# nrf5002 register map
Vendor: Nordic Semiconductor; Series: nRF50; File version: 1
CPU: CM0 r0p4, little endian, no MPU, no FPU, 2 interrupt priority bits, 32 interrupts
Registers are 32-bit, read-write, reset 0x0 unless marked. A register's access mark holds for its fields unless they carry their own. Offsets are from the block's base; [hi:lo] are bit positions; {n}, {i} and the like mark numbered series; 'fields as' and 'values as' point back to an identical list.

## RADIO (part 1 of 2) — 2.4 GHz radio
Base 0x40002000
0x00 TASKS_TXEN wo — Enable RADIO in TX mode
  [0] TASKS_TXEN
    1=Trigger task
0x04 TASKS_RXEN wo — Enable RADIO in RX mode
  [0] TASKS_RXEN
    1=Trigger task
0x08 TASKS_START wo — Start RADIO
  [0] TASKS_START
    1=Trigger task
0x0C TASKS_STOP wo — Stop RADIO
  [0] TASKS_STOP
    1=Trigger task
0x10 TASKS_DISABLE wo — Disable RADIO
  [0] TASKS_DISABLE
    1=Trigger task
0x14 TASKS_RSSISTART wo — Start the RSSI and take one single sample of the receive signal strength
  [0] TASKS_RSSISTART
    1=Trigger task
0x18 TASKS_RSSISTOP wo — Stop the RSSI measurement
  [0] TASKS_RSSISTOP
    1=Trigger task
0x1C TASKS_BCSTART wo — Start the bit counter
  [0] TASKS_BCSTART
    1=Trigger task
0x20 TASKS_BCSTOP wo — Stop the bit counter
  [0] TASKS_BCSTOP
    1=Trigger task
0x38 TASKS_CNTP_START wo — Start packet counter
  [0] TASKS_CNTP_START
    1=Trigger task
0x3C TASKS_CNTP_STOP wo — Stop packet counter
  [0] TASKS_CNTP_STOP
    1=Trigger task
0x40 TASKS_CNTP_CLEAR wo — Clear packet counter
  [0] TASKS_CNTP_CLEAR
    1=Trigger task
0x44 TASKS_DFESTART wo — Start an AoA/AoD procedure (antenna switching and baseband sampling)
  [0] TASKS_DFESTART
    1=Trigger task
0x48 TASKS_DFESTOP wo — Stop an AoA/AoD procedure
  [0] TASKS_DFESTOP
    1=Trigger task
0x50 TASKS_DMA_START wo — Start DMA transaction
  [0] TASKS_DMA_START
    1=Trigger task
0x54 TASKS_DMA_STOP wo — Stop ongoing DMA transaction
  [0] TASKS_DMA_STOP
    1=Trigger task
0x60 TASKS_ACQSTART wo — Start data acquisition
  [0] TASKS_ACQSTART
    1=Trigger task
0x64 TASKS_ACQSTOP wo — Stop data acquisition
  [0] TASKS_ACQSTOP
    1=Trigger task
0x68 TASKS_PCGC_PCP2_ZERO wo — Zero penalty
  [0] TASKS_PCGC_PCP2_ZERO
    1=Trigger task
0x6C TASKS_PCGC_PCP2_FULL wo — Full penalty
  [0] TASKS_PCGC_PCP2_FULL
    1=Trigger task
0x70 TASKS_PCGC_PCP1_ZERO wo — Zero penalty
  [0] TASKS_PCGC_PCP1_ZERO
    1=Trigger task
0x74 TASKS_PCGC_PCP1_FULL wo — Full penalty
  [0] TASKS_PCGC_PCP1_FULL
    1=Trigger task
0x78 TASKS_PCGC_PCP0_ZERO wo — Zero penalty
  [0] TASKS_PCGC_PCP0_ZERO
    1=Trigger task
0x7C TASKS_PCGC_PCP0_FULL wo — Full penalty
  [0] TASKS_PCGC_PCP0_FULL
    1=Trigger task
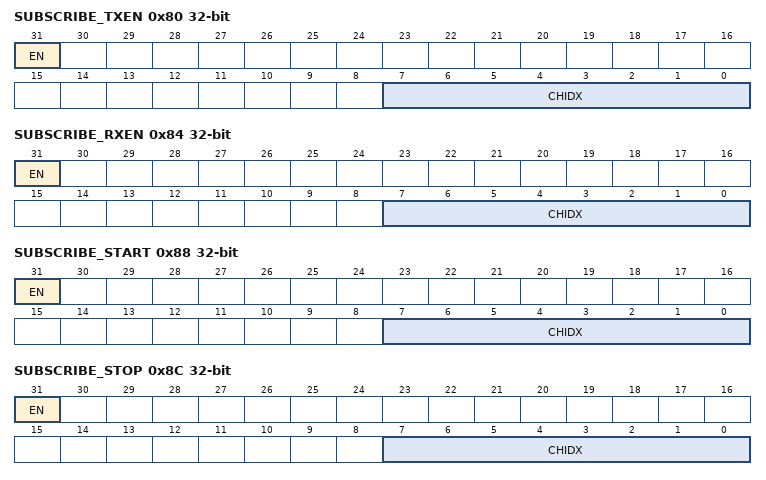
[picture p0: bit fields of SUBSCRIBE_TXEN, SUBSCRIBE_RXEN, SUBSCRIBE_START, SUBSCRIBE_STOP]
0x80 SUBSCRIBE_TXEN — Subscribe configuration for task TXEN
  [31] EN
    0=Disabled (Disable subscription); 1=Enabled (Enable subscription)
  [7:0] CHIDX — DPPI channel that task TXEN will subscribe to
0x84 SUBSCRIBE_RXEN — Subscribe configuration for task RXEN
  [31] EN
    values as SUBSCRIBE_TXEN.EN
  [7:0] CHIDX — DPPI channel that task RXEN will subscribe to
0x88 SUBSCRIBE_START — Subscribe configuration for task START
  [31] EN
    values as SUBSCRIBE_TXEN.EN
  [7:0] CHIDX — DPPI channel that task START will subscribe to
0x8C SUBSCRIBE_STOP — Subscribe configuration for task STOP
  [31] EN
    values as SUBSCRIBE_TXEN.EN
  [7:0] CHIDX — DPPI channel that task STOP will subscribe to
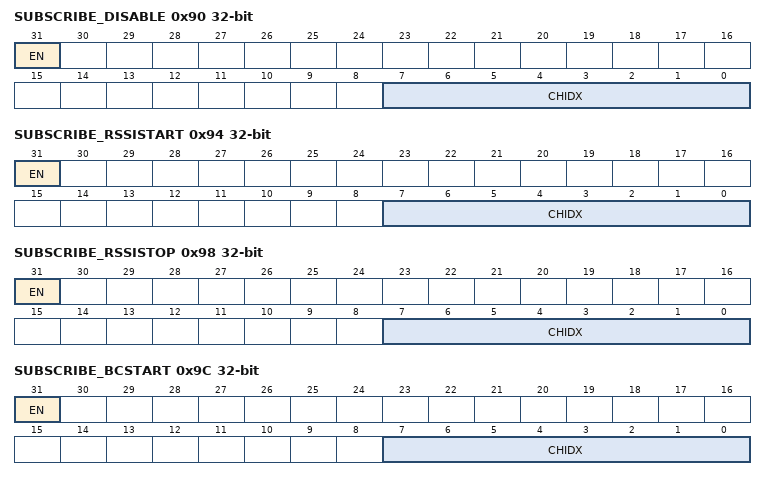
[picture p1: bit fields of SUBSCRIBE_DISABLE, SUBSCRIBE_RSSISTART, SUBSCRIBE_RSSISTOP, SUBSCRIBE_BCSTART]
0x90 SUBSCRIBE_DISABLE — Subscribe configuration for task DISABLE
  [31] EN
    values as SUBSCRIBE_TXEN.EN
  [7:0] CHIDX — DPPI channel that task DISABLE will subscribe to
0x94 SUBSCRIBE_RSSISTART — Subscribe configuration for task RSSISTART
  [31] EN
    values as SUBSCRIBE_TXEN.EN
  [7:0] CHIDX — DPPI channel that task RSSISTART will subscribe to
0x98 SUBSCRIBE_RSSISTOP — Subscribe configuration for task RSSISTOP
  [31] EN
    values as SUBSCRIBE_TXEN.EN
  [7:0] CHIDX — DPPI channel that task RSSISTOP will subscribe to
0x9C SUBSCRIBE_BCSTART — Subscribe configuration for task BCSTART
  [31] EN
    values as SUBSCRIBE_TXEN.EN
  [7:0] CHIDX — DPPI channel that task BCSTART will subscribe to
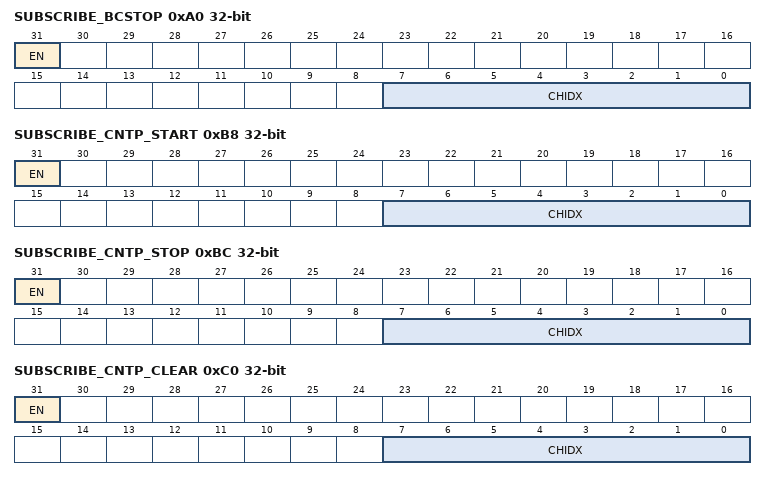
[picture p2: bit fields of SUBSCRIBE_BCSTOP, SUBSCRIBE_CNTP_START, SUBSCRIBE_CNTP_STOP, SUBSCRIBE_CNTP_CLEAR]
0xA0 SUBSCRIBE_BCSTOP — Subscribe configuration for task BCSTOP
  [31] EN
    values as SUBSCRIBE_TXEN.EN
  [7:0] CHIDX — DPPI channel that task BCSTOP will subscribe to
0xB8 SUBSCRIBE_CNTP_START — Subscribe configuration for task CNTP_START
  [31] EN
    values as SUBSCRIBE_TXEN.EN
  [7:0] CHIDX — DPPI channel that task CNTP_START will subscribe to
0xBC SUBSCRIBE_CNTP_STOP — Subscribe configuration for task CNTP_STOP
  [31] EN
    values as SUBSCRIBE_TXEN.EN
  [7:0] CHIDX — DPPI channel that task CNTP_STOP will subscribe to
0xC0 SUBSCRIBE_CNTP_CLEAR — Subscribe configuration for task CNTP_CLEAR
  [31] EN
    values as SUBSCRIBE_TXEN.EN
  [7:0] CHIDX — DPPI channel that task CNTP_CLEAR will subscribe to
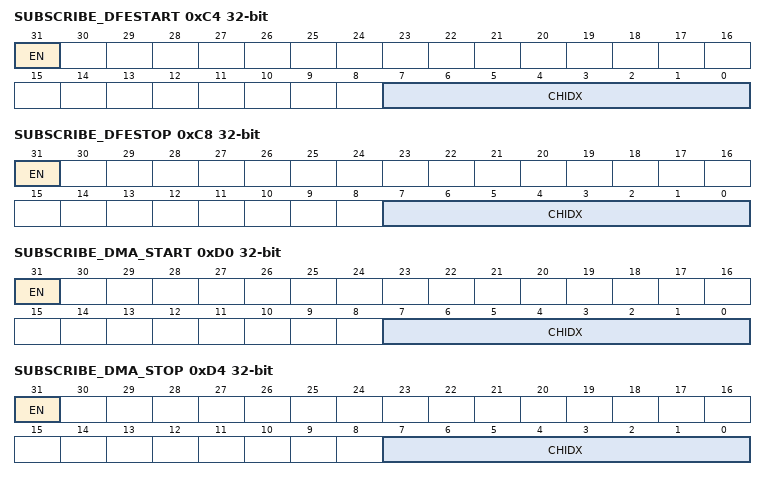
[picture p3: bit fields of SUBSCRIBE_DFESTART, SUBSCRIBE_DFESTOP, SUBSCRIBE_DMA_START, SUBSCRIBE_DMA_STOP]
0xC4 SUBSCRIBE_DFESTART — Subscribe configuration for task DFESTART
  [31] EN
    values as SUBSCRIBE_TXEN.EN
  [7:0] CHIDX — DPPI channel that task DFESTART will subscribe to
0xC8 SUBSCRIBE_DFESTOP — Subscribe configuration for task DFESTOP
  [31] EN
    values as SUBSCRIBE_TXEN.EN
  [7:0] CHIDX — DPPI channel that task DFESTOP will subscribe to
0xD0 SUBSCRIBE_DMA_START — Subscribe configuration for task DMA_START
  [31] EN
    values as SUBSCRIBE_TXEN.EN
  [7:0] CHIDX — DPPI channel that task DMA_START will subscribe to
0xD4 SUBSCRIBE_DMA_STOP — Subscribe configuration for task DMA_STOP
  [31] EN
    values as SUBSCRIBE_TXEN.EN
  [7:0] CHIDX — DPPI channel that task DMA_STOP will subscribe to
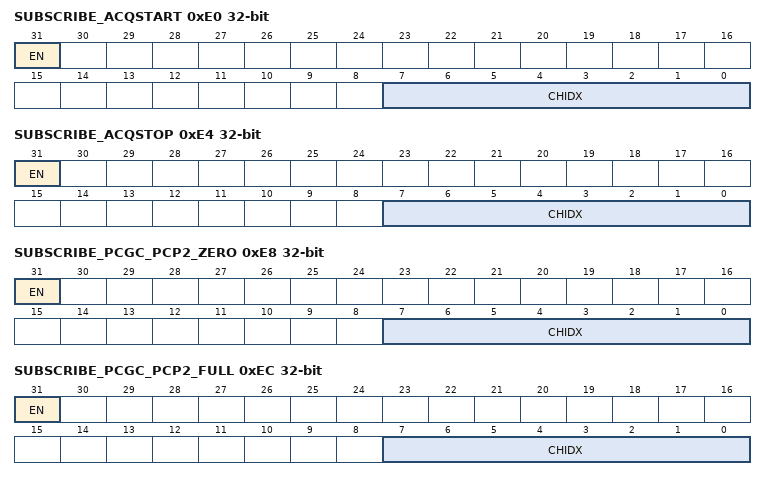
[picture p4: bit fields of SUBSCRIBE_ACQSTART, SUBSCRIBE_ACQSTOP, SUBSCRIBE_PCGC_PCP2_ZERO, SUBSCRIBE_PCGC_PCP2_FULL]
0xE0 SUBSCRIBE_ACQSTART — Subscribe configuration for task ACQSTART
  [31] EN
    values as SUBSCRIBE_TXEN.EN
  [7:0] CHIDX — DPPI channel that task ACQSTART will subscribe to
0xE4 SUBSCRIBE_ACQSTOP — Subscribe configuration for task ACQSTOP
  [31] EN
    values as SUBSCRIBE_TXEN.EN
  [7:0] CHIDX — DPPI channel that task ACQSTOP will subscribe to
0xE8 SUBSCRIBE_PCGC_PCP2_ZERO — Subscribe configuration for task PCGC_PCP2_ZERO
  [31] EN
    values as SUBSCRIBE_TXEN.EN
  [7:0] CHIDX — DPPI channel that task PCGC_PCP2_ZERO will subscribe to
0xEC SUBSCRIBE_PCGC_PCP2_FULL — Subscribe configuration for task PCGC_PCP2_FULL
  [31] EN
    values as SUBSCRIBE_TXEN.EN
  [7:0] CHIDX — DPPI channel that task PCGC_PCP2_FULL will subscribe to
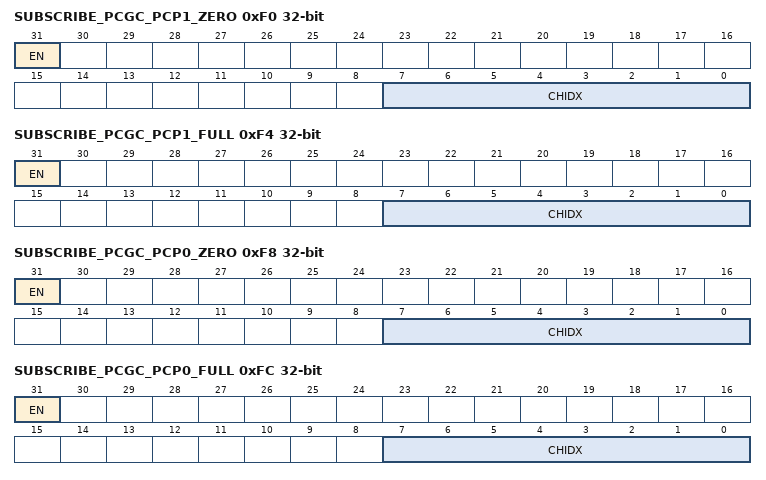
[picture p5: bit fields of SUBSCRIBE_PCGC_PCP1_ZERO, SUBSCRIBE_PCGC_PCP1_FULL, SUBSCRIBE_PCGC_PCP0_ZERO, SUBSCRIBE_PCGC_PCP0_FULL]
0xF0 SUBSCRIBE_PCGC_PCP1_ZERO — Subscribe configuration for task PCGC_PCP1_ZERO
  [31] EN
    values as SUBSCRIBE_TXEN.EN
  [7:0] CHIDX — DPPI channel that task PCGC_PCP1_ZERO will subscribe to
0xF4 SUBSCRIBE_PCGC_PCP1_FULL — Subscribe configuration for task PCGC_PCP1_FULL
  [31] EN
    values as SUBSCRIBE_TXEN.EN
  [7:0] CHIDX — DPPI channel that task PCGC_PCP1_FULL will subscribe to
0xF8 SUBSCRIBE_PCGC_PCP0_ZERO — Subscribe configuration for task PCGC_PCP0_ZERO
  [31] EN
    values as SUBSCRIBE_TXEN.EN
  [7:0] CHIDX — DPPI channel that task PCGC_PCP0_ZERO will subscribe to
0xFC SUBSCRIBE_PCGC_PCP0_FULL — Subscribe configuration for task PCGC_PCP0_FULL
  [31] EN
    values as SUBSCRIBE_TXEN.EN
  [7:0] CHIDX — DPPI channel that task PCGC_PCP0_FULL will subscribe to
0x100 EVENTS_READY — RADIO has ramped up and is ready to be started
  [0] EVENTS_READY
    0=NotGenerated (Event not generated); 1=Generated (Event generated)
0x104 EVENTS_ADDRESS — Address sent or received
  [0] EVENTS_ADDRESS
    values as EVENTS_READY.EVENTS_READY
0x108 EVENTS_PAYLOAD — Packet payload sent or received
  [0] EVENTS_PAYLOAD
    values as EVENTS_READY.EVENTS_READY
0x10C EVENTS_END — Packet sent or received
  [0] EVENTS_END
    values as EVENTS_READY.EVENTS_READY
0x110 EVENTS_DISABLED — RADIO has been disabled
  [0] EVENTS_DISABLED
    values as EVENTS_READY.EVENTS_READY
0x114 EVENTS_DEVMATCH — A device address match occurred on the last received packet
  [0] EVENTS_DEVMATCH
    values as EVENTS_READY.EVENTS_READY
0x118 EVENTS_DEVMISS — No device address match occurred on the last received packet
  [0] EVENTS_DEVMISS
    values as EVENTS_READY.EVENTS_READY
0x11C EVENTS_RSSIEND — Sampling of receive signal strength complete
  [0] EVENTS_RSSIEND
    values as EVENTS_READY.EVENTS_READY
0x128 EVENTS_BCMATCH — Bit counter reached bit count value
  [0] EVENTS_BCMATCH
    values as EVENTS_READY.EVENTS_READY
0x12C EVENTS_CTEEND — End of CTE
  [0] EVENTS_CTEEND
    values as EVENTS_READY.EVENTS_READY
0x130 EVENTS_CRCOK — Packet received with CRC ok
  [0] EVENTS_CRCOK
    values as EVENTS_READY.EVENTS_READY
0x134 EVENTS_CRCERROR — Packet received with CRC error
  [0] EVENTS_CRCERROR
    values as EVENTS_READY.EVENTS_READY
0x154 EVENTS_TXREADY — RADIO has ramped up and is ready to be started TX path
  [0] EVENTS_TXREADY
    values as EVENTS_READY.EVENTS_READY
0x158 EVENTS_RXREADY — RADIO has ramped up and is ready to be started RX path
  [0] EVENTS_RXREADY
    values as EVENTS_READY.EVENTS_READY
0x15C EVENTS_MHRMATCH — MAC header match found
  [0] EVENTS_MHRMATCH
    values as EVENTS_READY.EVENTS_READY
0x160 EVENTS_ACQEND — ACQDMA EasyDMA buffer full
  [0] EVENTS_ACQEND
    values as EVENTS_READY.EVENTS_READY
0x164 EVENTS_ACQREADY — ACQDMA EasyDMA sample ready
  [0] EVENTS_ACQREADY
    values as EVENTS_READY.EVENTS_READY
0x16C EVENTS_PHYEND — Generated when last bit is sent on air, or received from air
  [0] EVENTS_PHYEND
    values as EVENTS_READY.EVENTS_READY
0x170 EVENTS_CTEPRESENT — CTE is present (early warning right after receiving CTEInfo byte)
  [0] EVENTS_CTEPRESENT
    values as EVENTS_READY.EVENTS_READY
0x174 EVENTS_CTEWARNING — CTE is present, but CTEType or CTETime is out of valid range (early warning right after receiving CTEinfo byte)
  [0] EVENTS_CTEWARNING
    values as EVENTS_READY.EVENTS_READY
0x178 EVENTS_DFEEND — When both antenna switching AND direction finding sampling have completed
  [0] EVENTS_DFEEND
    values as EVENTS_READY.EVENTS_READY
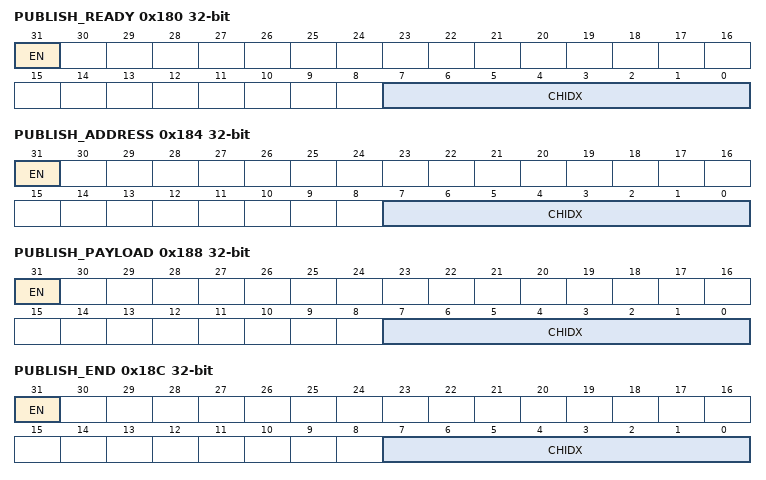
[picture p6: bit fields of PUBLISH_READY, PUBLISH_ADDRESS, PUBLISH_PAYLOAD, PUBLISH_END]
0x180 PUBLISH_READY — Publish configuration for event READY
  [31] EN
    0=Disabled (Disable publishing); 1=Enabled (Enable publishing)
  [7:0] CHIDX — DPPI channel that event READY will publish to
0x184 PUBLISH_ADDRESS — Publish configuration for event ADDRESS
  [31] EN
    values as PUBLISH_READY.EN
  [7:0] CHIDX — DPPI channel that event ADDRESS will publish to
0x188 PUBLISH_PAYLOAD — Publish configuration for event PAYLOAD
  [31] EN
    values as PUBLISH_READY.EN
  [7:0] CHIDX — DPPI channel that event PAYLOAD will publish to
0x18C PUBLISH_END — Publish configuration for event END
  [31] EN
    values as PUBLISH_READY.EN
  [7:0] CHIDX — DPPI channel that event END will publish to
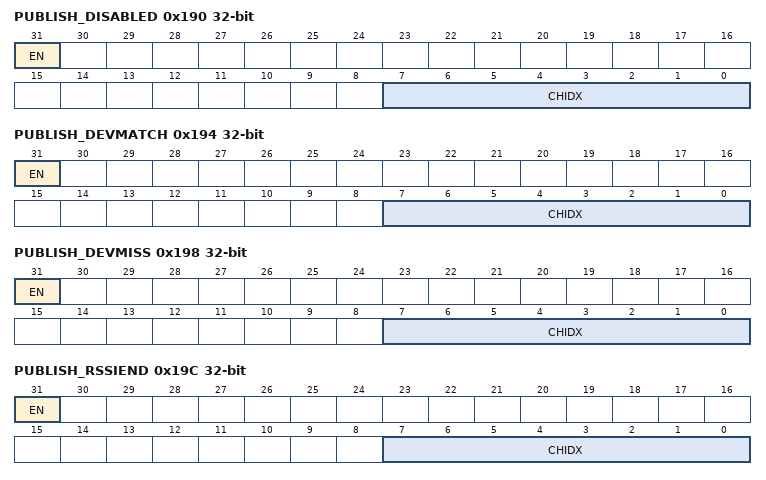
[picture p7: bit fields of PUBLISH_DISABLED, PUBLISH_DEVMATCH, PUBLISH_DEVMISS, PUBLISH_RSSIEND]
0x190 PUBLISH_DISABLED — Publish configuration for event DISABLED
  [31] EN
    values as PUBLISH_READY.EN
  [7:0] CHIDX — DPPI channel that event DISABLED will publish to
0x194 PUBLISH_DEVMATCH — Publish configuration for event DEVMATCH
  [31] EN
    values as PUBLISH_READY.EN
  [7:0] CHIDX — DPPI channel that event DEVMATCH will publish to
0x198 PUBLISH_DEVMISS — Publish configuration for event DEVMISS
  [31] EN
    values as PUBLISH_READY.EN
  [7:0] CHIDX — DPPI channel that event DEVMISS will publish to
0x19C PUBLISH_RSSIEND — Publish configuration for event RSSIEND
  [31] EN
    values as PUBLISH_READY.EN
  [7:0] CHIDX — DPPI channel that event RSSIEND will publish to
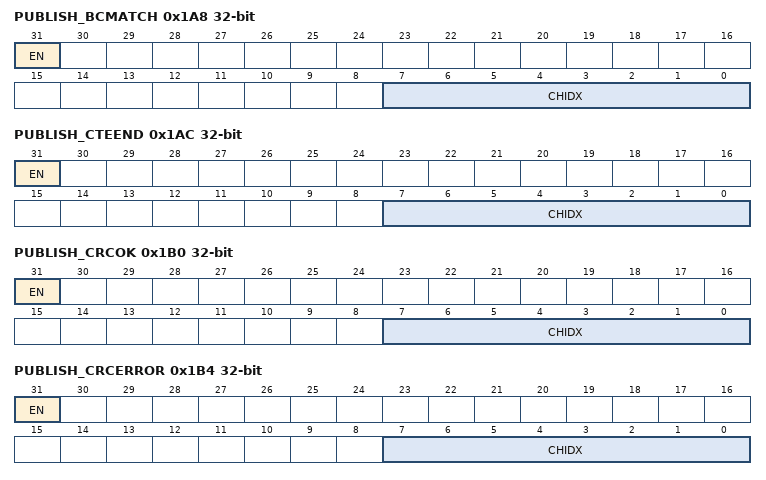
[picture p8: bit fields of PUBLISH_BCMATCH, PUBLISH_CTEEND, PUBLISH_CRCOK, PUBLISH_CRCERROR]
0x1A8 PUBLISH_BCMATCH — Publish configuration for event BCMATCH
  [31] EN
    values as PUBLISH_READY.EN
  [7:0] CHIDX — DPPI channel that event BCMATCH will publish to
0x1AC PUBLISH_CTEEND — Publish configuration for event CTEEND
  [31] EN
    values as PUBLISH_READY.EN
  [7:0] CHIDX — DPPI channel that event CTEEND will publish to
0x1B0 PUBLISH_CRCOK — Publish configuration for event CRCOK
  [31] EN
    values as PUBLISH_READY.EN
  [7:0] CHIDX — DPPI channel that event CRCOK will publish to
0x1B4 PUBLISH_CRCERROR — Publish configuration for event CRCERROR
  [31] EN
    values as PUBLISH_READY.EN
  [7:0] CHIDX — DPPI channel that event CRCERROR will publish to
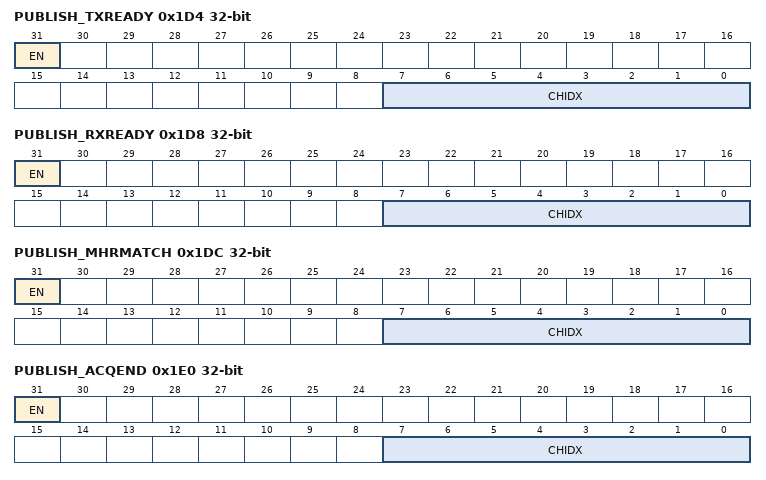
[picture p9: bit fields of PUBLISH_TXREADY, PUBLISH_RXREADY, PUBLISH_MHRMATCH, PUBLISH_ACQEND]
0x1D4 PUBLISH_TXREADY — Publish configuration for event TXREADY
  [31] EN
    values as PUBLISH_READY.EN
  [7:0] CHIDX — DPPI channel that event TXREADY will publish to
0x1D8 PUBLISH_RXREADY — Publish configuration for event RXREADY
  [31] EN
    values as PUBLISH_READY.EN
  [7:0] CHIDX — DPPI channel that event RXREADY will publish to
0x1DC PUBLISH_MHRMATCH — Publish configuration for event MHRMATCH
  [31] EN
    values as PUBLISH_READY.EN
  [7:0] CHIDX — DPPI channel that event MHRMATCH will publish to
0x1E0 PUBLISH_ACQEND — Publish configuration for event ACQEND
  [31] EN
    values as PUBLISH_READY.EN
  [7:0] CHIDX — DPPI channel that event ACQEND will publish to
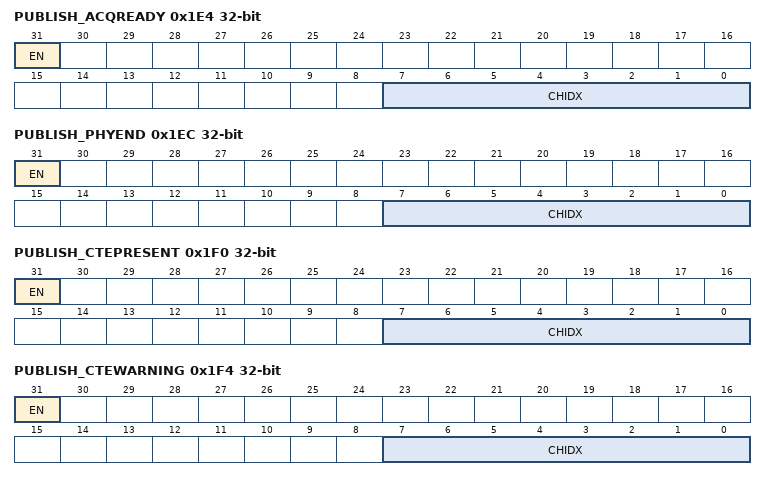
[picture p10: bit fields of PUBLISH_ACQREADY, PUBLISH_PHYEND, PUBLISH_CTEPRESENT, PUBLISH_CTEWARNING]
0x1E4 PUBLISH_ACQREADY — Publish configuration for event ACQREADY
  [31] EN
    values as PUBLISH_READY.EN
  [7:0] CHIDX — DPPI channel that event ACQREADY will publish to
0x1EC PUBLISH_PHYEND — Publish configuration for event PHYEND
  [31] EN
    values as PUBLISH_READY.EN
  [7:0] CHIDX — DPPI channel that event PHYEND will publish to
0x1F0 PUBLISH_CTEPRESENT — Publish configuration for event CTEPRESENT
  [31] EN
    values as PUBLISH_READY.EN
  [7:0] CHIDX — DPPI channel that event CTEPRESENT will publish to
0x1F4 PUBLISH_CTEWARNING — Publish configuration for event CTEWARNING
  [31] EN
    values as PUBLISH_READY.EN
  [7:0] CHIDX — DPPI channel that event CTEWARNING will publish to
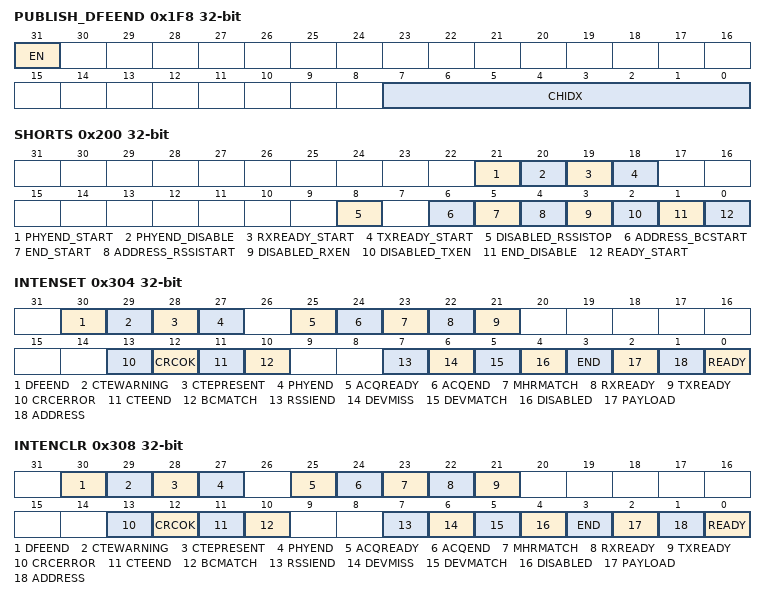
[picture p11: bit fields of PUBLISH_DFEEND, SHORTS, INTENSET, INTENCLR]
0x1F8 PUBLISH_DFEEND — Publish configuration for event DFEEND
  [31] EN
    values as PUBLISH_READY.EN
  [7:0] CHIDX — DPPI channel that event DFEEND will publish to
0x200 SHORTS — Shortcuts between local events and tasks
  [all] fields
    0=Disabled (Disable shortcut); 1=Enabled (Enable shortcut)
  [21] PHYEND_START — Shortcut between event PHYEND and task START
  [20] PHYEND_DISABLE — Shortcut between event PHYEND and task DISABLE
  [19] RXREADY_START — Shortcut between event RXREADY and task START
  [18] TXREADY_START — Shortcut between event TXREADY and task START
  [8] DISABLED_RSSISTOP — Shortcut between event DISABLED and task RSSISTOP
  [6] ADDRESS_BCSTART — Shortcut between event ADDRESS and task BCSTART
  [5] END_START — Shortcut between event END and task START
  [4] ADDRESS_RSSISTART — Shortcut between event ADDRESS and task RSSISTART
  [3] DISABLED_RXEN — Shortcut between event DISABLED and task RXEN
  [2] DISABLED_TXEN — Shortcut between event DISABLED and task TXEN
  [1] END_DISABLE — Shortcut between event END and task DISABLE
  [0] READY_START — Shortcut between event READY and task START
0x304 INTENSET — Enable interrupt
  [all] fields
    on read: 0=Disabled (Read: Disabled); 1=Enabled (Read: Enabled) | on write: 1=Set (Enable)
  [30] DFEEND — Write '1' to enable interrupt for event DFEEND
  [29] CTEWARNING — Write '1' to enable interrupt for event CTEWARNING
  [28] CTEPRESENT — Write '1' to enable interrupt for event CTEPRESENT
  [27] PHYEND — Write '1' to enable interrupt for event PHYEND
  [25] ACQREADY — Write '1' to enable interrupt for event ACQREADY
  [24] ACQEND — Write '1' to enable interrupt for event ACQEND
  [23] MHRMATCH — Write '1' to enable interrupt for event MHRMATCH
  [22] RXREADY — Write '1' to enable interrupt for event RXREADY
  [21] TXREADY — Write '1' to enable interrupt for event TXREADY
  [13] CRCERROR — Write '1' to enable interrupt for event CRCERROR
  [12] CRCOK — Write '1' to enable interrupt for event CRCOK
  [11] CTEEND — Write '1' to enable interrupt for event CTEEND
  [10] BCMATCH — Write '1' to enable interrupt for event BCMATCH
  [7] RSSIEND — Write '1' to enable interrupt for event RSSIEND
  [6] DEVMISS — Write '1' to enable interrupt for event DEVMISS
  [5] DEVMATCH — Write '1' to enable interrupt for event DEVMATCH
  [4] DISABLED — Write '1' to enable interrupt for event DISABLED
  [3] END — Write '1' to enable interrupt for event END
  [2] PAYLOAD — Write '1' to enable interrupt for event PAYLOAD
  [1] ADDRESS — Write '1' to enable interrupt for event ADDRESS
  [0] READY — Write '1' to enable interrupt for event READY
0x308 INTENCLR — Disable interrupt
  [all] fields
    on read: 0=Disabled (Read: Disabled); 1=Enabled (Read: Enabled) | on write: 1=Clear (Disable)
  [30] DFEEND — Write '1' to disable interrupt for event DFEEND
  [29] CTEWARNING — Write '1' to disable interrupt for event CTEWARNING
  [28] CTEPRESENT — Write '1' to disable interrupt for event CTEPRESENT
  [27] PHYEND — Write '1' to disable interrupt for event PHYEND
  [25] ACQREADY — Write '1' to disable interrupt for event ACQREADY
  [24] ACQEND — Write '1' to disable interrupt for event ACQEND
  [23] MHRMATCH — Write '1' to disable interrupt for event MHRMATCH
  [22] RXREADY — Write '1' to disable interrupt for event RXREADY
  [21] TXREADY — Write '1' to disable interrupt for event TXREADY
  [13] CRCERROR — Write '1' to disable interrupt for event CRCERROR
  [12] CRCOK — Write '1' to disable interrupt for event CRCOK
  [11] CTEEND — Write '1' to disable interrupt for event CTEEND
  [10] BCMATCH — Write '1' to disable interrupt for event BCMATCH
  [7] RSSIEND — Write '1' to disable interrupt for event RSSIEND
  [6] DEVMISS — Write '1' to disable interrupt for event DEVMISS
  [5] DEVMATCH — Write '1' to disable interrupt for event DEVMATCH
  [4] DISABLED — Write '1' to disable interrupt for event DISABLED
  [3] END — Write '1' to disable interrupt for event END
  [2] PAYLOAD — Write '1' to disable interrupt for event PAYLOAD
  [1] ADDRESS — Write '1' to disable interrupt for event ADDRESS
  [0] READY — Write '1' to disable interrupt for event READY
0x400 CRCSTATUS ro
  [0] CRCSTATUS — CRC status of packet received
    0=CRCError (Packet received with CRC error); 1=CRCOk (Packet received with CRC ok)
0x408 RXMATCH ro — Received address
  [2:0] RXMATCH
0x40C RXCRC ro — CRC field of previously received packet
  [23:0] RXCRC
0x410 DAI ro — Device address match index
  [2:0] DAI
0x414 PDUSTAT ro — Payload status
  [0] PDUSTAT — Status on payload length vs. PCNF1.MAXLEN
    0=LessThan (Payload less than PCNF1.MAXLEN); 1=GreaterThan (Payload greater than PCNF1.MAXLEN)
0x418 DMA_STAT ro — DMA byte count
  [7:0] DMA_STAT — Number of bytes in previous DMA transfer.
0x420 PLL_CAL_VCO ro — PLL Calibration
  [4:0] PLL_CAL_VCO — Holds capacitance-setting for PLL after automatic setting has been performed. This value is updated at the end of the calibration interval.
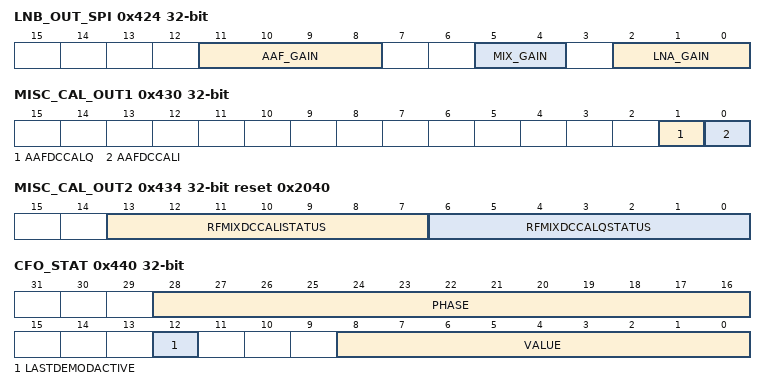
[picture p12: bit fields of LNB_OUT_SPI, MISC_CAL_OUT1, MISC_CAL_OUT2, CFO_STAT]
0x424 LNB_OUT_SPI ro — Readout of gain settings set by the AGC. They are sampled at EVENTS_ADDRESS and when triggering TASKS_RSSISTART
  [11:8] AAF_GAIN
  [5:4] MIX_GAIN
  [2:0] LNA_GAIN — Readout of LNA gain setting. This is a function of received signal strength.
0x430 MISC_CAL_OUT1 ro — Misc cal readouts
  [1] AAFDCCALQ — High when AAF Q channel offset is positive : compare signal for calibration
  [0] AAFDCCALI — High when AAF I channel offset is positive : compare signal for calibration
0x434 MISC_CAL_OUT2 ro reset 0x2040 — Misc cal readouts
  [13:7] RFMIXDCCALISTATUS — dc calibration of I channel when aafCalOvrEn = 1
  [6:0] RFMIXDCCALQSTATUS — dc calibration of Q channel when aafCalOvrEn = 1
0x440 CFO_STAT ro — Carrier freq. offset estimate
  [28:16] PHASE — Readout of last valid phase set in correlator (hypermode only) (signed)
  [12] LASTDEMODACTIVE — 0: Standard mode was used last 1: Hypermode was last used
  [8:0] VALUE — Readout of last valid decision level set in BitSlicer (signed)
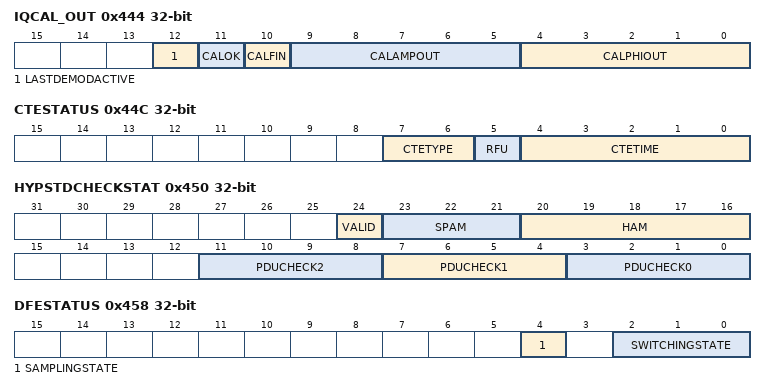
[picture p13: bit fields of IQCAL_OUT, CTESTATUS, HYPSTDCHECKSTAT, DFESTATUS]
0x444 IQCAL_OUT ro — Test: IandQ gain/phase mismatch calibration values out
  [12] LASTDEMODACTIVE — Mode last used
    0=Standard mode last used; 1=Hyper mode last used
  [11] CALOK — calibration succeed
  [10] CALFIN — calibration finished
  [9:5] CALAMPOUT — readout of IandQ gain calibration value
  [4:0] CALPHIOUT — readout of IandQ phase calibration value
0x448 PBCAL_OUT ro reset 0x1 — Test: PB calibration values out
  [0] PBREADY — PBIAS ready flag (bias outputs stable)
0x44C CTESTATUS ro — CTEInfo parsed from received packet
  [7:6] CTETYPE — CTEType parsed from packet
  [5] RFU — RFU parsed from packet
  [4:0] CTETIME — CTETime parsed from packet
0x450 HYPSTDCHECKSTAT — Address Check Override
  [24] VALID — Valid flag bit
  [23:21] SPAM — Time distance #bit clock cycles from AAmatchHyp.
  [20:16] HAM — Hamming distance between std demod AA15:0 and expected AA15:0.
  [11:8] PDUCHECK2 — Number of bits where Std and Hyper demodulator disagrees for maximum latency.
  [7:4] PDUCHECK1 — Number of bits where Std and Hyper demodulator disagrees for medium latency.
  [3:0] PDUCHECK0 — Number of bits where Std and Hyper demodulator disagrees for minimum latency.
0x454 HYPSTDAADIFFVEC — Address Diff Vector
  [15:0] DIFF — Hyper AA15:0 and Std AA15:0 differs.
0x458 DFESTATUS ro — DFE status information
  [4] SAMPLINGSTATE — Internal state of sampling state machine
    0=Idle (Sampling state Idle); 1=Sampling state Sampling
  [2:0] SWITCHINGSTATE — Internal state of switching state machine
    0=Idle (Switching state Idle); 1=Offset (Switching state Offset); 2=Guard (Switching state Guard); 3=Ref (Switching state Ref); 4=Switching state Switching; 5=Ending (Switching state Ending)
0x504 PACKETPTR reset 0x1000000 — Packet pointer
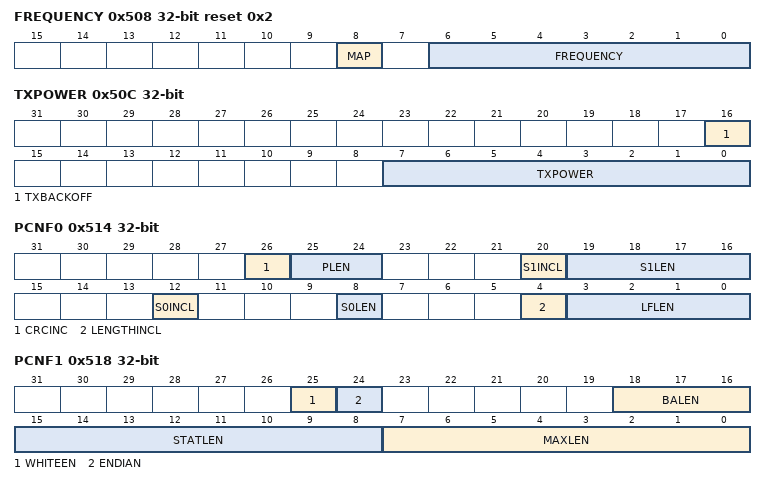
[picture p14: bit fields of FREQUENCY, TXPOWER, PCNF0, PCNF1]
0x508 FREQUENCY reset 0x2
  [8] MAP — Channel map selection.
    0=Default (Channel map between 2400 MHZ .. 2500 MHz); 1=Low (Channel map between 2360 MHZ .. 2460 MHz)
  [6:0] FREQUENCY — Radio channel frequency
0x50C TXPOWER — Output power
  [16] TXBACKOFF — Reduce output power by 0.5 dB relative to the setting in TXPOWER.
    0=DISABLE (Output power will be as specified in TXPOWER.); 1=ENABLE (Output power will equal TXPOWER - 0.5 dB.)
  [7:0] TXPOWER — RADIO output power
    {v}=Pos{v}dBm (+{v} dBm) (v=2..9); 0=0dBm; 252=Neg4dBm (-4 dBm); 248=Neg8dBm (-8 dBm); 244=Neg12dBm (-12 dBm); 240=Neg16dBm (-16 dBm); 236=Neg20dBm (-20 dBm); 226=Neg30dBm (Deprecated enumerator - -40 dBm); 216=Neg40dBm (-40 dBm)
0x510 MODE — Data rate and modulation
  [3:0] MODE — Radio data rate and modulation setting. The radio supports frequency-shift keying (FSK) modulation.
    0=Nrf_1Mbit (1 Mbps Nordic proprietary radio mode); 1=Nrf_2Mbit (2 Mbps Nordic proprietary radio mode); 2=Nrf_250Kbit (Deprecated enumerator - 250 kbps Nordic proprietary radio mode); 3=Ble_1Mbit (1 Mbps BLE); 4=Ble_2Mbit (2 Mbps BLE)
0x514 PCNF0 — Packet configuration register 0
  [26] CRCINC — Indicates if LENGTH field contains CRC or not
    0=Exclude (LENGTH does not contain CRC); 1=Include (LENGTH includes CRC)
  [25:24] PLEN — Length of preamble on air. Decision point: TASKS_START task
    0=8-bit preamble; 1=16-bit preamble
  [20] S1INCL — Include or exclude S1 field in RAM
    0=Automatic (Include S1 field in RAM only if S1LEN > 0); 1=Include (Always include S1 field in RAM independent of S1LEN)
  [19:16] S1LEN — Length on air of S1 field in number of bits.
  [12] S0INCL — Include or exclude S0 field in RAM
    0=Automatic (Include S0 field only if S0LEN > 0)
  [8] S0LEN — Length on air of S0 field in number of bytes.
  [4] LENGTHINCL — Include or exclude LENGTH field in RAM
    0=Automatic (Include LENGTH field in RAM only if LFLEN > 0)
  [3:0] LFLEN — Length on air of LENGTH field in number of bits.
0x518 PCNF1 — Packet configuration register 1
  [25] WHITEEN — Enable or disable packet whitening
    0=Disabled; 1=Enabled
  [24] ENDIAN — On-air endianness of packet, this applies to the S0, LENGTH, S1, and the PAYLOAD fields.
    0=Little (Least significant bit on air first); 1=Big (Most significant bit on air first)
  [18:16] BALEN — Base address length in number of bytes
  [15:8] STATLEN — Static length in number of bytes
  [7:0] MAXLEN — Maximum length of packet payload. If the packet payload is larger than MAXLEN, the radio will truncate the payload to MAXLEN.
0x51C BASE0 — Base address 0
0x520 BASE1 — Base address 1
0x524 PREFIX0 — Prefixes bytes for logical addresses 0-3
  [8n+7:8n] AP{n} (n=0..3) — Address prefix {n}.
0x528 PREFIX1 — Prefixes bytes for logical addresses 4-7
  [8n-25:8n-32] AP{n} (n=4..7) — Address prefix {n}.
0x52C TXADDRESS — Transmit address select
  [2:0] TXADDRESS
0x530 RXADDRESSES — Receive address select
  [16] HYPER — Hypermode settings
    0=B0 (Use hypermode for address ADDR0 (base address 0 RADIO.BASE0)); 1=B1 (From all of the enabled addresses among ADDR1 through ADDR7, the address ADDRn with the highest index number 'n' will use hypermode (base address 1 RADIO.BASE1))
  [n] ADDR{n} (n=0..7) — Enable or disable reception on logical address {n}.
    0=Disabled; 1=Enabled
0x534 CRCCNF — CRC configuration
  [9:8] SKIPADDR — Include or exclude packet address field out of CRC calculation.
    0=Include (CRC calculation includes address field); 1=Skip (CRC calculation does not include address field. The CRC calculation will start at the first byte after the address.)
  [1:0] LEN — CRC length in number of bytes.
    0=Disabled (CRC length is zero and CRC calculation is disabled); 1=One (CRC length is one byte and CRC calculation is enabled); 2=Two (CRC length is two bytes and CRC calculation is enabled); 3=Three (CRC length is three bytes and CRC calculation is enabled)
0x538 CRCPOLY — CRC polynomial
  [23:0] CRCPOLY
0x53C CRCINIT — CRC initial value
  [23:0] CRCINIT
0x544 TIFS — Interframe spacing in us
  [9:0] TIFS
0x548 RSSISAMPLE ro
  [6:0] RSSISAMPLE
0x54C RSSI_CONFIG — RSSI resolution
  [31] ENABLE — if '1' enable override for this register
  [14:8] RSSICAL — RSSI calibration value
0x550 STATE ro — Current radio state
  [3:0] STATE
    0=Disabled (RADIO is in the Disabled state); 1=RxRu (RADIO is in the RXRU state); 2=RxIdle (RADIO is in the RXIDLE state); 3=Rx (RADIO is in the RX state); 4=RxDisable (RADIO is in the RXDISABLED state); 9=TxRu (RADIO is in the TXRU state); 10=TxIdle (RADIO is in the TXIDLE state); 11=Tx (RADIO is in the TX state); 12=TxDisable (RADIO is in the TXDISABLED state)
0x554 DATAWHITEIV reset 0x40 — Data whitening initial value
  [6:0] DATAWHITEIV — Data whitening initial value. Bit 6 is hardwired to '1', writing '0' to it has no effect, and it will always be read back and used by the device as '1'.
0x55C DMA_MAXLEN reset 0x103 — DMA max length
  [8:0] DMA_MAXLEN — Maximum size of DMA transfer in number of bytes
0x560 BCC — Bit counter compare
0x568 AACHKOVERRIDE reset 0x2600000 — Address Check Override
  [29:28] ENCONCRX — Enable concurrent RX AA match mechanism
    0=BleLR (AA match to primary advertising packets on BLE LR); 1=Concurrent AA match to primary advertising packets on both BLE LR (hyper) and BLE 1M (standard), the winner takes over the packet parser; 2=Ble1Mbit (AA match to primary advertising packets on BLE 1M only); 3=DoNotUse (Illegal combination)
  [26:24] SYMSBEFORESFD — Number of preamble symbols before SFD to match, by default 2 symbols.
  [21] PERFECTADDRWINDOW — Enable timing accurate address match window in demodulator
    0=DISABLE (The address window has some margin); 1=ENABLE (The address window spans only one bit)
  [20] ALLOWADDRMATCHEARLY — Enable ignore std AA checker before shift register filled
    0=ENABLE; 1=DISABLE
  [19] DISABLE — Disable std AA checker
    0=ENABLE (Enable std AA checker); 1=DISABLE (Disable std AA checker)
  [18] BYPASS — Bypass majority vote
    0=PASS (Majority vote); 1=BYPASS (Bypass through majority vote)
  [17] ENABLE — Enable AA bit 15 check
    0=AA16_31 (Enable AA16..31); 1=AA15_31 (Enable AA15..31)
  [9:0] ENDCOUNTHYPSTD — Defines maximum number of PDU bits to compare between Hyper and Std demodulator
0x56C PB_TEST reset 0xC0000880 — Test: PB calibration
  [31] OVRENVBGTRIM — if '1' enable override for VBGTRIM
  [30] OVRENPBIBPSTRIM — if '1' enable override for PBIBPSTRIM
  [11:8] VBGTRIM — Trim code for VBG to FS_VCOREG
  [7:4] PBIBPSTRIM — Trim code for IBPS currents
0x570 PACKET_CNTR1 ro — Test: PER msrmnts
  [15:0] COUNTER — Packet counter value
0x574 PACKET_CNTR2 ro — Test: PER msrmnts
  [31:16] NORMAL — Packet counter value (number of packets with addressmatch ok)
  [15:0] HYPER — Number of detected correlator syncs
0x578 IQCAL_TEST reset 0x2800 — Test: IandQ gain/phase mismatch calibration control
  [15:8] IQCALWAIT — Settling time (in number of 16 MHz clock periods) for rssi input to stabilize
  [2:1] MODE — IQCal search mode
  [0] RUN — Run IanQ calibration procedure
0x580 DBC_COEFFS — Test and Debug: DBC coefficients override
  [12] OVRALWAYSUPDATE — Zero means coefficients only updated when needed (default), set to 1 coefficients are always updated when the radio is enabled.
  [11] PADDRUPDATEOVRVAL
  [10] PADDRUPDATEOVREN
0x584 FS_CONFIG reset 0x91B08 — Fs config (ana+dig)
  [31] OVRENFSMODULATORDELAY — if '1' enable override for FSMODULATORDELAY
  [30] OVRENFSGFSKBYPASS — if '1' enable override for FSGFSKBYPASS
  [29] OVRVCOVDD — Use 1v3 supply for FS_VCO power
    0=Ficr (Value of FICR.RADIOTRIM01->FSPFDCPREG is used in stead of FS_CONFIG.VCOVDD); 1=Par (Use FS_CONFIG.VCOVDD)
  [28:24] FSVCOCAPOVRD — Override value for external control of VCO calibration, 0x00 for off
  [23:22] FSVCOKMODOVRD — Override modulator gain distribution (between analog/digital)
  [21:18] FSMODULATORDELAY — programmable delay
  [17] FSGFSKBYPASS — '1': Unfiltered FSK transmission
  [16] FSGFSKBT — Adjust GFSK bandwidth. '1': 0.6, '0': 0.55
  [15:12] FSPDCURR — Analog configuration register: Phase detector current
  [11:8] FSVCOCURR — Analog configuration register: VCO current
  [5] FSVCOSHUTUP
  [4:3] FSPDDLY — configuration register: Phase detector delay
  [2] FSPDCKDISABLE — Shut off FS_PD by clamping the clocks
  [1] FSPFDCPREG — Value used for RADIO->FS_CONFIG.VCOVDD when RADIO->FS_CONFIG.OVRVCOVDD = 0
    0=Disable (Use power filter on PFD and charge pump in radio); 1=Enable (Use LDO and PFD and charge pump in radio)
  [0] SSEL — Deprecated field - Sideband select (1=upper/0=lower)
0x588 FS_TEST reset 0x4008 — Fs misc test
  [31] OVRENFSDEVOVERRIDE — if '1' enable override for FSDEVOVERRIDE
  [30] OVRENFSTXMODULATORGAIN — if '1' enable override for FSTXMODULATORGAIN
  [27] FSTXSDMALWAYSON — 0 : TxSDM on only in TX mode. 1 : TxSDM on in both TX and RX mode
  [26] LOIFOVERRIDEFREQUENCY — 0 : 1 MHz. 1 : 2 MHz
  [25] LOIFOVERRIDESIDEBAND — 1 : Upper sideband of LO. 0 : Lower sideband of LO
  [24] LOIFOVERRIDEON — 1 : LO IF override is on. 0 : LO IF override is off
  [21:16] FSDEVOVERRIDE — External control of frequency deviation, value overrides calculated FS and TX multipliers, 0x00 for off
  [14:8] FSTXMODULATORGAIN — Adjust TX path modulation gain
  [7] FSTESTMODULATOR — 1: Disables TX path during LO modulation test. 0: Normal mode
  [6] FSTESTUSE2NDSDM — 1: Switch to single loop SDM in FsSDM
  [5] FSTESTFSDITHEROFF — 1: Shutoff dither in FsSDM
  [4] FSTESTTXDITHEROFF — 1: Shutoff dither in TxSDM
  [3:0] FSDEVCHANNELGRADIENT — FS deviation scale factor gradient over channel no
